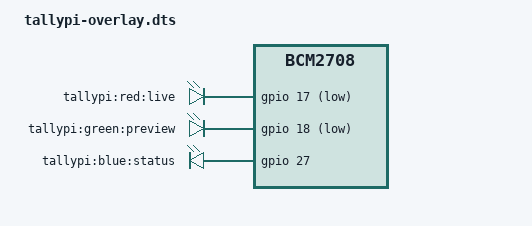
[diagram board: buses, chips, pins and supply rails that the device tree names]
/dts-v1/;
/plugin/;

/ {
	compatible = "brcm,bcm2708";

	fragment@0 {
		target = <&leds>;
		__overlay__ {
			led_red: live {
				label = "tallypi:red:live";
				gpios = <&gpio 17 1>;
			};

			led_green: preview {
				label = "tallypi:green:preview";
				gpios = <&gpio 18 1>;
			};

			led_blue: status {
				label = "tallypi:blue:status";
				gpios = <&gpio 27 0>;
			};
		};
	};

	__overrides__ {
		red_gpio = <&led_red>,"gpios:4";
		red_activelow = <&led_red>,"gpios:8";

		green_gpio = <&led_green>,"gpios:4";
		green_activelow = <&led_green>,"gpios:8";

		blue_gpio = <&led_blue>,"gpios:4";
		blue_activelow = <&led_blue>,"gpios:8";
	};
};
